# soc register map
Vendor: litex
Registers are 32-bit, read-write, reset 0x0 unless marked. A register's access mark holds for its fields unless they carry their own. Offsets are from the block's base; lines under a group give offsets from that group; [hi:lo] are bit positions; {n}, {i} and the like mark numbered series; 'fields as' and 'values as' point back to an identical list; <NAME> marks a mode.

## Memory map
0xE0000000 CTRL size 0xC
0xE0001800 UART size 0x40
0xE0002000 POWER size 0x8
0xE0002800 TIMER0 size 0x20
0xE0003000 COM size 0x14
0xE0003800 WIFI size 0x24
0xE0004800 I2C size 0xC
0xE0005000 PICORVSPI size 0x14
0xE0007800 TICKTIMER size 0x20

## Interrupts
0 uart (UART)
1 timer0 (TIMER0)
2 i2c (I2C)
3 wifi (WIFI)
4 com (COM)

## Further device data
memoryRegions:
  VEXRISCV_DEBUG baseAddress=0xF00F0000 size=0x00000100
  SRAM baseAddress=0x10000000 size=0x00020000
  SPIFLASH baseAddress=0x20000000 size=0x00100000
  I2C baseAddress=0xB0000000 size=0x00000040
  COM baseAddress=0xD0000000 size=0x00000004
  CSR baseAddress=0xE0000000 size=0x00010000

## CTRL
Base 0xE0000000
0x00 RESET — Write a ``1`` to this register to reset the SoC.
  [0] reset
0x04 SCRATCH reset 0x12345678 — Use this register as a scratch space to verify that software read/write accesses to the Wishbone/CSR bus are working correctly. The initial reset value of 0x1234578 can be used to verify endianness.
0x08 BUS_ERRORS ro — Total number of Wishbone bus errors (timeouts) since start.

## UART
Base 0xE0001800
0x00 RXTX
  [7:0] rxtx
0x04 TXFULL ro
  [0] txfull
0x08 RXEMPTY ro
  [0] rxempty
0x0C EV_STATUS
  [1:0] status
0x10 EV_PENDING
  [1:0] pending
0x14 EV_ENABLE
  [1:0] enable
0x18 TXEMPTY ro
  [0] txempty
0x1C RXFULL ro
  [0] rxfull
0x20 XOVER_RXTX
  [7:0] xover_rxtx
0x24 XOVER_TXFULL ro
  [0] xover_txfull
0x28 XOVER_RXEMPTY ro
  [0] xover_rxempty
0x2C XOVER_EV_STATUS
  [1:0] xover_ev_status
0x30 XOVER_EV_PENDING
  [1:0] xover_ev_pending
0x34 XOVER_EV_ENABLE
  [1:0] xover_ev_enable
0x38 XOVER_TXEMPTY ro
  [0] xover_txempty
0x3C XOVER_RXFULL ro
  [0] xover_rxfull

## POWER
Base 0xE0002000
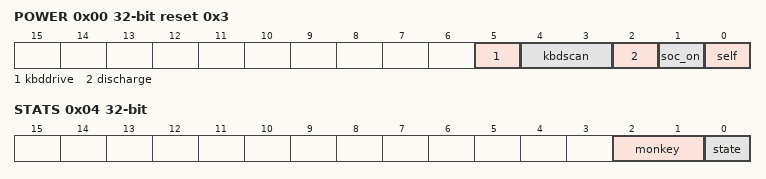
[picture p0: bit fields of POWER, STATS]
0x00 POWER reset 0x3
  [5] kbddrive — Writing `1` to this drives the input scan row to 0. Do this prior to reading to mitigate noise
  [4:3] kbdscan — Writing `1` to this forces the power-down keyboard scan event on the respective mon bit
  [2] discharge — Writing `1` to this connects a low-value resistor across FPGA domain supplies to force a full discharge
  [1] soc_on — Writing `1` to this powers on the SoC
  [0] self — Writing `1` to this keeps the EC powered on
0x04 STATS ro
  [2:1] monkey — Power-on key monitor input
  [0] state — Current power state of the SOC

## TIMER0
Base 0xE0002800
0x00 LOAD — Load value when Timer is (re-)enabled. In One-Shot mode, the value written to this register specifies the Timer's duration in clock cycles.
0x04 RELOAD — Reload value when Timer reaches ``0``. In Periodic mode, the value written to this register specify the Timer's period in clock cycles.
0x08 EN — Enable flag of the Timer. Set this flag to ``1`` to enable/start the Timer. Set to ``0`` to disable the Timer.
  [0] en
0x0C UPDATE_VALUE — Update trigger for the current countdown value. A write to this register latches the current countdown value to ``value`` register.
  [0] update_value
0x10 VALUE ro — Latched countdown value. This value is updated by writing to ``update_value``.
0x14 EV_STATUS
  [0] status
0x18 EV_PENDING
  [0] pending
0x1C EV_ENABLE
  [0] enable

## COM
Base 0xE0003000
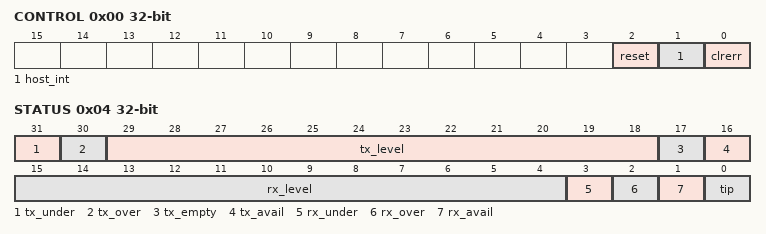
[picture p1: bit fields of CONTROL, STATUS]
0x00 CONTROL
  [2] reset — Reset the fifos
  [1] host_int — 0->1 raises an interrupt to the COM host
  [0] clrerr — Clear FIFO error flags
0x04 STATUS ro
  [31] tx_under — Set when Tx FIFO underflows
  [30] tx_over — Set when Tx FIFO overflows
  [29:18] tx_level — Level of Tx FIFO
  [17] tx_empty — Set when Tx FIFO is empty
  [16] tx_avail — Set when Tx FIFO has space for new content
  [15:4] rx_level — Level of Rx FIFO
  [3] rx_under — Set if Rx FIFO underflows
  [2] rx_over — Set if Rx FIFO has overflowed
  [1] rx_avail — Set when Rx FIFO has new, valid contents to read
  [0] tip — Set when transaction is in progress
0x08 EV_STATUS
  [2:0] status
0x0C EV_PENDING
  [2:0] pending
0x10 EV_ENABLE
  [2:0] enable

## WIFI
Base 0xE0003800
0x00 TX — Tx data, for COPI
  [15:0] tx
0x04 RX ro — Rx data, from CIPO
  [15:0] rx
0x08 CS
  [0] cs — Writing `1` to this asserts cs_n, that is, brings it low; writing `0`, brings it high
0x0C CONTROL
  [0] go — Initiate a SPI cycle by writing a `1`. Does not automatically clear.
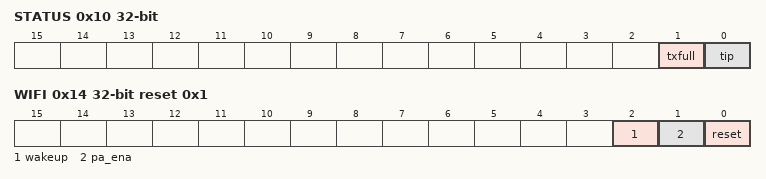
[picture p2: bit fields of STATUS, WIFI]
0x10 STATUS ro
  [1] txfull — Set when Tx register is full
  [0] tip — Set when transaction is in progress
0x14 WIFI reset 0x1
  [2] wakeup — Wakeup the wifi chip
  [1] pa_ena — Mapped to PA_ENABLE for wifi (only useful if configured in wifi firmware)
  [0] reset — Write `1` to this register to reset the wifi chip; write `0` to enable normal operation
0x18 EV_STATUS
  [0] status
0x1C EV_PENDING
  [0] pending
0x20 EV_ENABLE
  [0] enable

## I2C
Base 0xE0004800
0x00 EV_STATUS
  [3:0] status
0x04 EV_PENDING
  [3:0] pending
0x08 EV_ENABLE
  [3:0] enable

## PICORVSPI
Base 0xE0005000
0x00 CFG1
  [7:0] cfg1
0x04 CFG2
  [7:0] cfg2
0x08 CFG3 reset 0x24
  [7:0] cfg3
0x0C CFG4
  [7:0] cfg4
0x10 STAT ro

## TICKTIMER
Base 0xE0007800
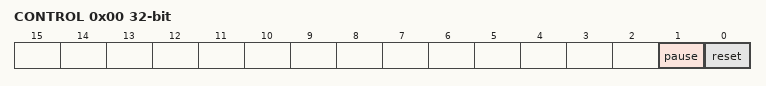
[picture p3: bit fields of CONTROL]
0x00 CONTROL
  [1] pause — Write a `1` to this field to pause counting, 0 for free-run
  [0] reset — Write a `1` to this bit to reset the count to 0
0x04 TIME1 ro — Bits 32-39 of `TICKTIMER_TIME`. Elapsed time in systicks
  [31:0] time
0x08 TIME0 ro — Bits 0-31 of `TICKTIMER_TIME`.
  [31:0] time
0x0C MSLEEP_TARGET1 — Bits 32-63 of `TICKTIMER_MSLEEP_TARGET`. Target time in 1.0ms ticks
  [31:0] msleep_target
0x10 MSLEEP_TARGET0 — Bits 0-31 of `TICKTIMER_MSLEEP_TARGET`.
  [31:0] msleep_target
0x14 EV_STATUS
  [0] status
0x18 EV_PENDING
  [0] pending
0x1C EV_ENABLE
  [0] enable
